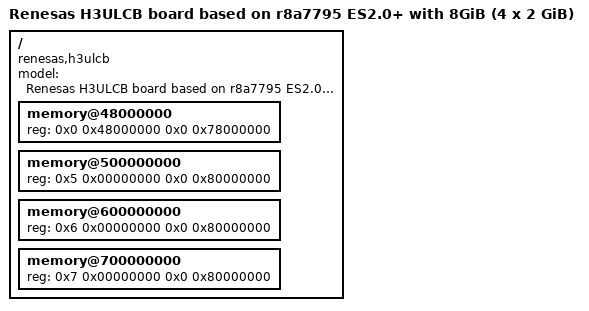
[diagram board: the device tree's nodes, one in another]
// SPDX-License-Identifier: GPL-2.0
/*
 * Device Tree Source for the H3ULCB (R-Car Starter Kit Premier) board
 *
 * Copyright (C) 2020 Renesas Electronics Corporaton.
 */

#include "r8a7795-h3ulcb.dts"

/ {
	model = "Renesas H3ULCB board based on r8a7795 ES2.0+ with 8GiB (4 x 2 GiB)";
	compatible = "renesas,h3ulcb", "renesas,r8a7795";

	memory@48000000 {
		device_type = "memory";
		/* first 128MB is reserved for secure area. */
		reg = <0x0 0x48000000 0x0 0x78000000>;
	};

	memory@500000000 {
		device_type = "memory";
		reg = <0x5 0x00000000 0x0 0x80000000>;
	};

	memory@600000000 {
		device_type = "memory";
		reg = <0x6 0x00000000 0x0 0x80000000>;
	};

	memory@700000000 {
		device_type = "memory";
		reg = <0x7 0x00000000 0x0 0x80000000>;
	};
};
